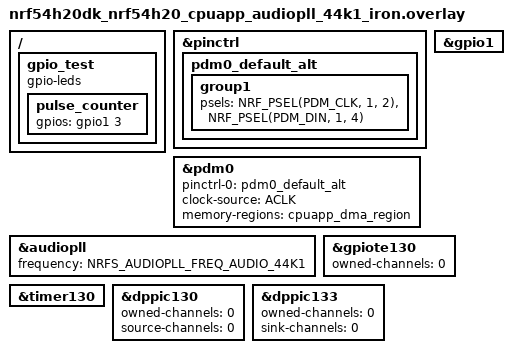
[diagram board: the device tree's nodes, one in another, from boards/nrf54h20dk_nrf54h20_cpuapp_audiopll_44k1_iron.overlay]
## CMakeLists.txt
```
#
# Copyright (c) 2024 Nordic Semiconductor ASA
#
# SPDX-License-Identifier: LicenseRef-Nordic-5-Clause
#

cmake_minimum_required(VERSION 3.20.0)

find_package(Zephyr REQUIRED HINTS $ENV{ZEPHYR_BASE})
project(pdm_loopback)

target_sources(app PRIVATE src/main.c)
if(CONFIG_SOC_NRF54H20_IRON)
  target_sources(app PRIVATE periphconf_migrated_src/periphconf_migrated_from_uicr.c)
endif()
```

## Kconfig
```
#
# Copyright (c) 2024 Nordic Semiconductor ASA
#
# SPDX-License-Identifier: LicenseRef-Nordic-5-Clause
#

source "Kconfig.zephyr"

config TEST_PDM_SAMPLING_RATE
	int "PDM sample rate in Hz"
	default 10000
	help
	  The test will use it to define frequency of PDM sampling and
	  calculate the size of the buffer.

config TEST_PDM_EXPECTED_FREQUENCY
	int "Expected PDM_CLK frequency in Hz"
	default 1000000
	help
	  The test will use it to confirm that the captured PDM_CLK
	  frequency in correct.

config TEST_PDM_SAMPLING_TIME
	int "PDM sampling time for one block in ms"
	default 100
	help
	  The test will use it to calculate the size of data block and
	  determine the period of capturing timer.

config TEST_USE_DMM
	bool "Use of DMM pre-allocation"
	help
	  The test will use it to determine whether to prealocate DMM
	  buffer or use regular mem slab and allocate dmm buffer inside
	  PDM driver.
```

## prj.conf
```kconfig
#
# Copyright (c) 2024 Nordic Semiconductor ASA
#
# SPDX-License-Identifier: LicenseRef-Nordic-5-Clause
#

CONFIG_ZTEST=y
CONFIG_TEST_USERSPACE=y

CONFIG_AUDIO=y
CONFIG_AUDIO_DMIC=y
CONFIG_GPIO=y
CONFIG_NRFX_GPPI=y
CONFIG_NRFX_TIMER=y
```

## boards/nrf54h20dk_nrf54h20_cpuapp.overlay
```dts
/*
 * Copyright (c) 2024 Nordic Semiconductor ASA
 *
 * SPDX-License-Identifier: LicenseRef-Nordic-5-Clause
 */

/ {
	gpio_test {
		compatible = "gpio-leds";

		pulse_counter: pulse_counter {
			gpios = <&gpio1 3 GPIO_ACTIVE_HIGH>;
		};
	};
};

&pinctrl {
	pdm0_default_alt: pdm0_default_alt {
		group1 {
			psels = <NRF_PSEL(PDM_CLK, 1, 2)>,
				<NRF_PSEL(PDM_DIN, 1, 4)>;
		};
	};
};

pdm_dev: &pdm0 {
	status = "okay";
	pinctrl-0 = <&pdm0_default_alt>;
	pinctrl-names = "default";
	clock-source = "PCLK32M";
	memory-regions = <&cpuapp_dma_region>;
};

&gpio1 {
	status = "okay";
};

&gpiote130 {
	owned-channels = <0>;
	status = "okay";
};

&timer130 {
	status = "okay";
};
```

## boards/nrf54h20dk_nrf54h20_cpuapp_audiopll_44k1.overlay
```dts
/*
 * Copyright (c) 2025 Nordic Semiconductor ASA
 *
 * SPDX-License-Identifier: LicenseRef-Nordic-5-Clause
 */

/ {
	gpio_test {
		compatible = "gpio-leds";

		pulse_counter: pulse_counter {
			gpios = <&gpio1 3 GPIO_ACTIVE_HIGH>;
		};
	};
};

&pinctrl {
	pdm0_default_alt: pdm0_default_alt {
		group1 {
			psels = <NRF_PSEL(PDM_CLK, 1, 2)>,
				<NRF_PSEL(PDM_DIN, 1, 4)>;
		};
	};
};

pdm_dev: &pdm0 {
	status = "okay";
	pinctrl-0 = <&pdm0_default_alt>;
	pinctrl-names = "default";
	clock-source = "ACLK";
	memory-regions = <&cpuapp_dma_region>;
};

&audiopll {
	status = "okay";
	frequency = <NRFS_AUDIOPLL_FREQ_AUDIO_44K1>;
};

&gpio1 {
	status = "okay";
};

&gpiote130 {
	owned-channels = <0>;
	status = "okay";
};

&timer130 {
	status = "okay";
};
```

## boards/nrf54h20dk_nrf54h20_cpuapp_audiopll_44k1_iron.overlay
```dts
/*
 * Copyright (c) 2025 Nordic Semiconductor ASA
 *
 * SPDX-License-Identifier: LicenseRef-Nordic-5-Clause
 */

/ {
	gpio_test {
		compatible = "gpio-leds";
		pulse_counter: pulse_counter {
			gpios = <&gpio1 3 GPIO_ACTIVE_HIGH>;
		};
	};
};

&pinctrl {
	pdm0_default_alt: pdm0_default_alt {
		group1 {
			psels = <NRF_PSEL(PDM_CLK, 1, 2)>,
				<NRF_PSEL(PDM_DIN, 1, 4)>;
		};
	};
};

pdm_dev: &pdm0 {
	status = "okay";
	pinctrl-0 = <&pdm0_default_alt>;
	pinctrl-names = "default";
	clock-source = "ACLK";
	memory-regions = <&cpuapp_dma_region>;
};

&audiopll {
	status = "okay";
	frequency = <NRFS_AUDIOPLL_FREQ_AUDIO_44K1>;
};

&gpio1 {
	status = "okay";
};

&gpiote130 {
	owned-channels = <0>;
	status = "okay";
};

&timer130 {
	status = "okay";
};

&dppic130 {
	owned-channels = <0>;
	source-channels = <0>;
	status = "okay";
};

&dppic133 {
	owned-channels = <0>;
	sink-channels = <0>;
	status = "okay";
};
```

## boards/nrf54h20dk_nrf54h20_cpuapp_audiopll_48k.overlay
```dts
/*
 * Copyright (c) 2025 Nordic Semiconductor ASA
 *
 * SPDX-License-Identifier: LicenseRef-Nordic-5-Clause
 */

/ {
	gpio_test {
		compatible = "gpio-leds";

		pulse_counter: pulse_counter {
			gpios = <&gpio1 3 GPIO_ACTIVE_HIGH>;
		};
	};
};

&pinctrl {
	pdm0_default_alt: pdm0_default_alt {
		group1 {
			psels = <NRF_PSEL(PDM_CLK, 1, 2)>,
				<NRF_PSEL(PDM_DIN, 1, 4)>;
		};
	};
};

pdm_dev: &pdm0 {
	status = "okay";
	pinctrl-0 = <&pdm0_default_alt>;
	pinctrl-names = "default";
	clock-source = "ACLK";
	memory-regions = <&cpuapp_dma_region>;
};

&audiopll {
	status = "okay";
	frequency = <NRFS_AUDIOPLL_FREQ_AUDIO_48K>;
};

&gpio1 {
	status = "okay";
};

&gpiote130 {
	owned-channels = <0>;
	status = "okay";
};

&timer130 {
	status = "okay";
};
```

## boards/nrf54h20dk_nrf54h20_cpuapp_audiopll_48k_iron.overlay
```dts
/*
 * Copyright (c) 2025 Nordic Semiconductor ASA
 *
 * SPDX-License-Identifier: LicenseRef-Nordic-5-Clause
 */

/ {
	gpio_test {
		compatible = "gpio-leds";
		pulse_counter: pulse_counter {
			gpios = <&gpio1 3 GPIO_ACTIVE_HIGH>;
		};
	};
};

&pinctrl {
	pdm0_default_alt: pdm0_default_alt {
		group1 {
			psels = <NRF_PSEL(PDM_CLK, 1, 2)>,
				<NRF_PSEL(PDM_DIN, 1, 4)>;
		};
	};
};

pdm_dev: &pdm0 {
	status = "okay";
	pinctrl-0 = <&pdm0_default_alt>;
	pinctrl-names = "default";
	clock-source = "ACLK";
	memory-regions = <&cpuapp_dma_region>;
};

&audiopll {
	status = "okay";
	frequency = <NRFS_AUDIOPLL_FREQ_AUDIO_48K>;
};

&gpio1 {
	status = "okay";
};

&gpiote130 {
	owned-channels = <0>;
	status = "okay";
};

&timer130 {
	status = "okay";
};

&dppic130 {
	owned-channels = <0>;
	source-channels = <0>;
	status = "okay";
};

&dppic133 {
	owned-channels = <0>;
	sink-channels = <0>;
	status = "okay";
};
```

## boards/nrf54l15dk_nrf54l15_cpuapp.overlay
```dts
/*
 * Copyright (c) 2024 Nordic Semiconductor ASA
 *
 * SPDX-License-Identifier: LicenseRef-Nordic-5-Clause
 */

/ {
	gpio_test {
		compatible = "gpio-leds";

		pulse_counter: pulse_counter {
			gpios = <&gpio1 11 GPIO_ACTIVE_HIGH>;
		};
	};
};

&pinctrl {
	pdm20_default_alt: pdm20_default_alt {
		group1 {
			psels = <NRF_PSEL(PDM_CLK, 1, 10)>,
				<NRF_PSEL(PDM_DIN, 1, 12)>;
		};
	};
};

pdm_dev: &pdm20 {
	status = "okay";
	pinctrl-0 = <&pdm20_default_alt>;
	pinctrl-names = "default";
	clock-source = "PCLK32M";
};

&gpio1 {
	status = "okay";
};

&timer00 {
	status = "okay";
};
```

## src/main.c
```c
/*
 * Copyright (c) 2024 Nordic Semiconductor ASA
 *
 * SPDX-License-Identifier: LicenseRef-Nordic-5-Clause
 */

#include <zephyr/kernel.h>
#include <zephyr/ztest.h>
#include <zephyr/device.h>
#include <zephyr/audio/dmic.h>
#include <zephyr/drivers/gpio.h>
#include <helpers/nrfx_gppi.h>
#include <nrfx_timer.h>
#include <nrfx_gpiote.h>
#include <gpiote_nrfx.h>
#if defined(CONFIG_HAS_NORDIC_DMM)
#include <dmm.h>
#endif

#define PDM_SAMPLING_RATE   CONFIG_TEST_PDM_SAMPLING_RATE
#define PDM_SAMPLING_RATE_DUMMY  32000
#define PDM_EXPECTED_FREQ   CONFIG_TEST_PDM_EXPECTED_FREQUENCY
#define PDM_SAMPLING_TIME   CONFIG_TEST_PDM_SAMPLING_TIME
#define PDM_READ_TIMEOUT    1000

#define SAMPLE_BIT_WIDTH 16
#define BYTES_PER_SAMPLE sizeof(int16_t)

#define BLOCK_SIZE(_sample_rate, _number_of_channels) \
	(BYTES_PER_SAMPLE * (_sample_rate * PDM_SAMPLING_TIME / 1000) * _number_of_channels)

#define MAX_BLOCK_SIZE   BLOCK_SIZE(PDM_SAMPLING_RATE, 1)
#define BLOCK_COUNT      4
#define SAMPLING_RATIO   PDM_SAMPLING_TIME / 1000 * BLOCK_COUNT / 2

#if CONFIG_TEST_USE_DMM
struct k_mem_slab mem_slab;
char __aligned(WB_UP(4)) mem_slab_buffer[BLOCK_COUNT * WB_UP(MAX_BLOCK_SIZE)]
					 DMM_MEMORY_SECTION(DT_NODELABEL(pdm_dev));
#else
K_MEM_SLAB_DEFINE_STATIC(mem_slab, MAX_BLOCK_SIZE, BLOCK_COUNT, 4);
#endif

#define CLOCK_INPUT_PIN	NRF_DT_GPIOS_TO_PSEL(DT_NODELABEL(pulse_counter), gpios)

#define NODE_AUDIOPLL DT_NODELABEL(audiopll)

#if DT_NODE_HAS_STATUS_OKAY(NODE_AUDIOPLL)
#include <zephyr/drivers/clock_control/nrf_clock_control.h>

const struct device *audiopll_dev = DEVICE_DT_GET(NODE_AUDIOPLL);
static K_SEM_DEFINE(audiopll_sem, 0, 1);

static void audiopll_notify_cb(struct onoff_manager *mgr,
			       struct onoff_client *cli,
			       uint32_t state,
			       int res)
{
	ARG_UNUSED(mgr);
	ARG_UNUSED(cli);
	ARG_UNUSED(state);
	ARG_UNUSED(res);

	k_sem_give(&audiopll_sem);
}
#endif

static const struct device *const pdm_dev = DEVICE_DT_GET(DT_NODELABEL(pdm_dev));
static struct pcm_stream_cfg stream_config, stream_config_dummy;
static struct dmic_cfg pdm_cfg, pdm_cfg_dummy;

#if defined(NRF_TIMER00)
static nrfx_timer_t timer_instance = NRFX_TIMER_INSTANCE(NRF_TIMER00);
#elif defined(NRF_TIMER130)
static nrfx_timer_t timer_instance = NRFX_TIMER_INSTANCE(NRF_TIMER130);
#else
#error "No timer instance found"
#endif

void timer_handler(nrf_timer_event_t event, void *p_context)
{
	ARG_UNUSED(event);
	ARG_UNUSED(p_context);
}

static void *device_setup(void)
{
	int ret;

	ret = device_is_ready(pdm_dev);
	zassert_true(ret, "PDM device is not ready, return code = %d", ret);

#if CONFIG_TEST_USE_DMM
	ret = k_mem_slab_init(&mem_slab, mem_slab_buffer, WB_UP(MAX_BLOCK_SIZE), BLOCK_COUNT);
	zassert_true(ret >= 0, "Memory slab initialization failed, return code = %d", ret);
#endif

	return NULL;
}

static void setup(void *unused)
{
	ARG_UNUSED(unused);

	stream_config.pcm_width = SAMPLE_BIT_WIDTH;
	stream_config.pcm_rate = PDM_SAMPLING_RATE;
	stream_config.mem_slab = &mem_slab;
	stream_config.block_size = BLOCK_SIZE(PDM_SAMPLING_RATE, 1);

	pdm_cfg.io.min_pdm_clk_freq = 1000000;
	pdm_cfg.io.max_pdm_clk_freq = 2000000;
	pdm_cfg.io.min_pdm_clk_dc   = 40;
	pdm_cfg.io.max_pdm_clk_dc   = 60;
	pdm_cfg.streams = &stream_config,
	pdm_cfg.channel.req_num_streams = 1;
	pdm_cfg.channel.req_num_chan = 1;
	pdm_cfg.channel.req_chan_map_lo = dmic_build_channel_map(0, 0, PDM_CHAN_LEFT);

	/* Dummy cfg to test that reconfiguration works */
	stream_config_dummy.pcm_width = SAMPLE_BIT_WIDTH;
	stream_config_dummy.pcm_rate = PDM_SAMPLING_RATE_DUMMY;
	stream_config_dummy.mem_slab = &mem_slab;
	stream_config_dummy.block_size = BLOCK_SIZE(PDM_SAMPLING_RATE, 1);

	pdm_cfg_dummy.io.min_pdm_clk_freq = 1000000;
	pdm_cfg_dummy.io.max_pdm_clk_freq = 2000000;
	pdm_cfg_dummy.io.min_pdm_clk_dc   = 40;
	pdm_cfg_dummy.io.max_pdm_clk_dc   = 60;
	pdm_cfg_dummy.streams = &stream_config_dummy,
	pdm_cfg_dummy.channel.req_num_streams = 1;
	pdm_cfg_dummy.channel.req_num_chan = 1;
	pdm_cfg_dummy.channel.req_chan_map_lo = dmic_build_channel_map(0, 0, PDM_CHAN_LEFT);
}

static void teardown(void *unused)
{
	ARG_UNUSED(unused);

	int ret;

	ret = dmic_trigger(pdm_dev, DMIC_TRIGGER_STOP);
	zassert_true(ret >= 0, "PDM start trigger failed, return code = %d", ret);
}

static void capture_callback(struct k_timer *timer)
{
	ARG_UNUSED(timer);
	nrfx_timer_capture(&timer_instance, NRF_TIMER_CC_CHANNEL0);
}

K_TIMER_DEFINE(capture_timer, capture_callback, NULL);

static void pdm_transfer(const struct device *pdm_dev,
			   struct dmic_cfg *pdm_cfg,
			   size_t block_count)
{
	int ret;

#if PDM_SAMPLING_RATE != PDM_SAMPLING_RATE_DUMMY
	/* Dummy configuration to test if device can be reconfigured.
	 *
	 * When both configurations are the same, apply it only once
	 * to test that single configuration also works.
	 */
	ret = dmic_configure(pdm_dev, &pdm_cfg_dummy);
	zassert_true(ret >= 0, "PDM configuration failed, return code = %d", ret);
#endif

	ret = dmic_configure(pdm_dev, pdm_cfg);
	zassert_true(ret >= 0, "PDM configuration failed, return code = %d", ret);

	ret = dmic_trigger(pdm_dev, DMIC_TRIGGER_START);
	zassert_true(ret >= 0, "PDM start trigger failed, return code = %d", ret);

	/* Count clock cycles during 50% of transfer time. */
	k_timer_start(&capture_timer, K_MSEC(BLOCK_COUNT / 2 * PDM_SAMPLING_TIME), K_NO_WAIT);

	void *buffer;
	uint32_t size;

	ret = dmic_read(pdm_dev, 0, &buffer, &size, PDM_READ_TIMEOUT);
	zassert_true(ret >= 0, "PDM read failed, return code = %d", ret);

	k_mem_slab_free(&mem_slab, buffer);

	k_msleep(BLOCK_COUNT / 2 * PDM_SAMPLING_TIME);

	ret = dmic_trigger(pdm_dev, DMIC_TRIGGER_STOP);
	zassert_true(ret >= 0, "PDM stop trigger failed, return code = %d", ret);
}

ZTEST(pdm_loopback, test_pdm_configure)
{
	int ret;

	/* Not enough channels. */
	pdm_cfg.channel.req_num_chan = 0;
	ret = dmic_configure(pdm_dev, &pdm_cfg);
	zassert_true(ret == -EINVAL, "PDM configuration should fail, return code = %d", ret);

	/* Too many channels. */
	pdm_cfg.channel.req_num_chan = 3;
	ret = dmic_configure(pdm_dev, &pdm_cfg);
	zassert_true(ret == -EINVAL, "PDM configuration should fail, return code = %d", ret);

	/* Streams not equal to 1. */
	pdm_cfg.channel.req_num_chan = 1;
	pdm_cfg.channel.req_num_streams = 0;
	ret = dmic_configure(pdm_dev, &pdm_cfg);
	zassert_true(ret == -EINVAL, "PDM configuration should fail, return code = %d", ret);

	/* Streams not equal to 1. */
	pdm_cfg.channel.req_num_chan = 1;
	pdm_cfg.channel.req_num_streams = 2;
	ret = dmic_configure(pdm_dev, &pdm_cfg);
	zassert_true(ret == -EINVAL, "PDM configuration should fail, return code = %d", ret);

	/* Invalid sample bit width. */
	pdm_cfg.channel.req_num_streams = 1;
	pdm_cfg.streams->pcm_width = 32;
	ret = dmic_configure(pdm_dev, &pdm_cfg);
	zassert_true(ret == -EINVAL, "PDM configuration should fail, return code = %d", ret);

	/* Invalid sample rate, unable to provide suitable clock. */
	pdm_cfg.streams->pcm_width = SAMPLE_BIT_WIDTH;
	pdm_cfg.streams->pcm_rate = 100;
	ret = dmic_configure(pdm_dev, &pdm_cfg);
	zassert_true(ret == -EINVAL, "PDM configuration should fail, return code = %d", ret);

	/* Proper configuration. */
	pdm_cfg.streams->pcm_rate = PDM_SAMPLING_RATE;
	ret = dmic_configure(pdm_dev, &pdm_cfg);
	zassert_true(ret >= 0, "PDM configuration failed, return code = %d", ret);

	ret = dmic_trigger(pdm_dev, DMIC_TRIGGER_START);
	zassert_true(ret >= 0, "PDM start trigger failed, return code = %d", ret);

	/* Device is running, unable to configure. */
	pdm_cfg.streams->pcm_rate = PDM_SAMPLING_RATE;
	ret = dmic_configure(pdm_dev, &pdm_cfg);
	zassert_true(ret == -EBUSY, "PDM configuration should fail, return code = %d", ret);
}

ZTEST(pdm_loopback, test_start_trigger)
{
	int ret;

	/* Disable device. */
	pdm_cfg.streams->pcm_rate = 0;
	ret = dmic_configure(pdm_dev, &pdm_cfg);
	zassert_true(ret >= 0, "PDM configuration failed, return code = %d", ret);

	/* Device not configured. */
	ret = dmic_trigger(pdm_dev, DMIC_TRIGGER_START);
	zassert_true(ret == -EIO, "PDM start trigger should fail, return code = %d", ret);

	pdm_cfg.streams->pcm_rate = PDM_SAMPLING_RATE;
	ret = dmic_configure(pdm_dev, &pdm_cfg);
	zassert_true(ret >= 0, "PDM configuration failed, return code = %d", ret);

	/* Proper start. */
	ret = dmic_trigger(pdm_dev, DMIC_TRIGGER_START);
	zassert_true(ret >= 0, "PDM start trigger failed, return code = %d", ret);

	/* Multiple start triggers should return no error. */
	ret = dmic_trigger(pdm_dev, DMIC_TRIGGER_START);
	zassert_true(ret >= 0, "PDM start trigger failed, return code = %d", ret);
}

ZTEST(pdm_loopback, test_pdm_clk_frequency)
{
	int ret;

#if DT_NODE_HAS_STATUS_OKAY(NODE_AUDIOPLL)
	struct onoff_client cli;

	sys_notify_init_callback(&cli.notify, audiopll_notify_cb);

	ret = nrf_clock_control_request(audiopll_dev, NULL, &cli);
	zassert_true(ret >= 0, "Audiopll request failed, return code = %d", ret);

	ret = k_sem_take(&audiopll_sem, K_MSEC(100));
#endif

	uint8_t gpiote_channel;
	nrfx_gpiote_t gpiote_instance =
		GPIOTE_NRFX_INST_BY_NODE(NRF_DT_GPIOTE_NODE(DT_NODELABEL(pulse_counter), gpios));

	ret = nrfx_gpiote_channel_alloc(&gpiote_instance, &gpiote_channel);
	zassert_true(ret == 0, "GPIOTE channel allocation failed, return code = %d", ret);

	nrfx_gpiote_trigger_config_t trigger_cfg = {
		.p_in_channel = &gpiote_channel,
		.trigger = NRFX_GPIOTE_TRIGGER_LOTOHI,
	};

	nrf_gpio_pin_pull_t pull_cfg = NRFX_GPIOTE_DEFAULT_PULL_CONFIG;

	nrfx_gpiote_input_pin_config_t gpiote_cfg = {
		.p_pull_config = &pull_cfg,
		.p_trigger_config = &trigger_cfg,
	};

	ret = nrfx_gpiote_input_configure(&gpiote_instance, CLOCK_INPUT_PIN, &gpiote_cfg);
	zassert_true(ret == 0, "GPIOTE input configuration failed, return code = %d", ret);

	nrfx_gpiote_trigger_enable(&gpiote_instance, CLOCK_INPUT_PIN, false);

	nrfx_timer_config_t timer_config = NRFX_TIMER_DEFAULT_CONFIG(
					   NRFX_TIMER_BASE_FREQUENCY_GET(&timer_instance));
	timer_config.bit_width = NRF_TIMER_BIT_WIDTH_32;
	timer_config.mode      = NRF_TIMER_MODE_COUNTER;

	ret = nrfx_timer_init(&timer_instance, &timer_config, timer_handler);
	zassert_true(ret == 0,
		     "TIMER initialization failed, return code = 0x%08X", ret);

	nrfx_timer_enable(&timer_instance);

	nrfx_gppi_handle_t gppi_handle;
	uint32_t eep = nrfx_gpiote_in_event_address_get(&gpiote_instance, CLOCK_INPUT_PIN);
	uint32_t tep = nrfx_timer_task_address_get(&timer_instance, NRF_TIMER_TASK_COUNT);

	ret = nrfx_gppi_conn_alloc(eep, tep, &gppi_handle);
	zassert_equal(ret, 0, "GPPI channel allocation failed, return code = %d", ret);
	nrfx_gppi_conn_enable(gppi_handle);

	pdm_transfer(pdm_dev, &pdm_cfg, BLOCK_COUNT);

	uint32_t pulses = nrfx_timer_capture_get(&timer_instance, NRF_TIMER_CC_CHANNEL0);

	/* Assert that captured frequency is within 3% margin of expected one. */
	zassert_within(pulses, PDM_EXPECTED_FREQ * SAMPLING_RATIO,
		       PDM_EXPECTED_FREQ * SAMPLING_RATIO / 30,
		       "Captured incorrect frequency Hz. Captured pulses = %u, expected = %d",
		       pulses, PDM_EXPECTED_FREQ * SAMPLING_RATIO);

	/* Remove GPPI configuration. */
	nrfx_gppi_conn_disable(gppi_handle);
	nrfx_gppi_conn_free(eep, tep, gppi_handle);

	/* Remove GPIOTE configuration. */
	ret = nrfx_gpiote_pin_uninit(&gpiote_instance, CLOCK_INPUT_PIN);
	zexpect_true(ret == 0, "nrfx_gpiote_pin_uninit() ret %d", ret);
	nrfx_gpiote_trigger_disable(&gpiote_instance, CLOCK_INPUT_PIN);
	ret = nrfx_gpiote_channel_free(&gpiote_instance, gpiote_channel);
	zexpect_true(ret == 0, "nrfx_gpiote_channel_free() ret %d", ret);

	/* Remove NRFX Timer configuration. */
	nrfx_timer_disable(&timer_instance);
	nrfx_timer_uninit(&timer_instance);

#if DT_NODE_HAS_STATUS_OKAY(NODE_AUDIOPLL)
	ret = nrf_clock_control_release(audiopll_dev, NULL);
	zassert_true(ret >= 0, "Audiopll release failed, return code = %d", ret);
#endif
}

ZTEST_SUITE(pdm_loopback, NULL, device_setup, setup, teardown, NULL);
```
